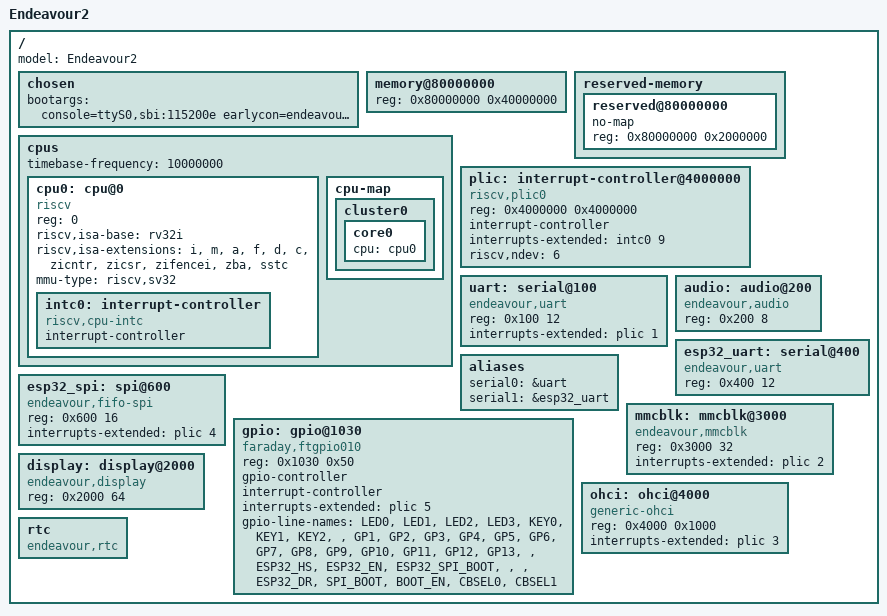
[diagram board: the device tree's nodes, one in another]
// SPDX-License-Identifier: GPL-3.0
/dts-v1/;

/ {
  #address-cells = <1>;
  #size-cells = <1>;
  model = "Endeavour2";

  chosen {
    bootargs = "console=ttyS0,sbi:115200e earlycon=endeavour_sbi root=/dev/mmcblk0p2";
  };

  memory@80000000 {
    device_type = "memory";
    reg = <0x80000000 0x40000000>;
  };

  reserved-memory {
    #address-cells = <1>;
    #size-cells = <1>;
    ranges;
    reserved@80000000 {
      no-map;
      reg = <0x80000000 0x2000000>;
    };
  };

  cpus {
    #address-cells = <1>;
    #size-cells = <0>;
    timebase-frequency = <10000000>;

    cpu0: cpu@0 {
      device_type = "cpu";
      reg = <0>;
      status = "okay";
      compatible = "riscv";
      riscv,isa-base = "rv32i";
      riscv,isa-extensions = "i", "m", "a", "f", "d", "c", "zicntr", "zicsr", "zifencei", "zba", "sstc";
      mmu-type = "riscv,sv32";
      intc0: interrupt-controller {
        #interrupt-cells = <1>;
        interrupt-controller;
        compatible = "riscv,cpu-intc";
      };
    };

    cpu-map {
      cluster0 {
        core0 { cpu = <&cpu0>; };
      };
    };
  };

  plic: interrupt-controller@4000000 {
    compatible = "riscv,plic0";
    reg = <0x4000000 0x4000000>;
    #address-cells = <0>;
    #size-cells = <0>;
    #interrupt-cells = <1>;
    interrupt-controller;
    interrupts-extended = <&intc0 9>;
    riscv,ndev = <6>;
  };

  uart: serial@100 {
    compatible = "endeavour,uart";
    reg = <0x100 12>;
    interrupts-extended = <&plic 1>;
  };

  audio: audio@200 {
    compatible = "endeavour,audio";
    reg = <0x200 8>;
  };

  esp32_uart: serial@400 {
    compatible = "endeavour,uart";
    reg = <0x400 12>;
  };

  aliases {
    serial0 = &uart;
    serial1 = &esp32_uart;
  };

  esp32_spi: spi@600 {
    compatible = "endeavour,fifo-spi";
    reg = <0x600 16>;
    interrupts-extended = <&plic 4>;
  };

  gpio: gpio@1030 {
    compatible = "faraday,ftgpio010";
    reg = <0x1030 0x50>;
    gpio-controller;
    #gpio-cells = <2>;
    interrupt-controller;
    interrupts-extended = <&plic 5>;
    #interrupt-cells = <2>;
    gpio-line-names =
      "LED0", "LED1", "LED2", "LED3",
      "KEY0", "KEY1", "KEY2", "",
      "GP1", "GP2", "GP3", "GP4",
      "GP5", "GP6", "GP7", "GP8",
      "GP9", "GP10", "GP11", "GP12",
      "GP13", "", "ESP32_HS", "ESP32_EN",
      "ESP32_SPI_BOOT", "", "", "ESP32_DR",
      "SPI_BOOT", "BOOT_EN", "CBSEL0", "CBSEL1";
  };

  mmcblk: mmcblk@3000 {
    compatible = "endeavour,mmcblk";
    reg = <0x3000 32>;
    interrupts-extended = <&plic 2>;
  };

  display: display@2000 {
    compatible = "endeavour,display";
    reg = <0x2000 64>;
  };

  ohci: ohci@4000 {
    compatible = "generic-ohci";
    reg = <0x4000 0x1000>;
    status = "okay";
    interrupts-extended = <&plic 3>;
  };

  rtc {
    compatible = "endeavour,rtc";
  };

};
